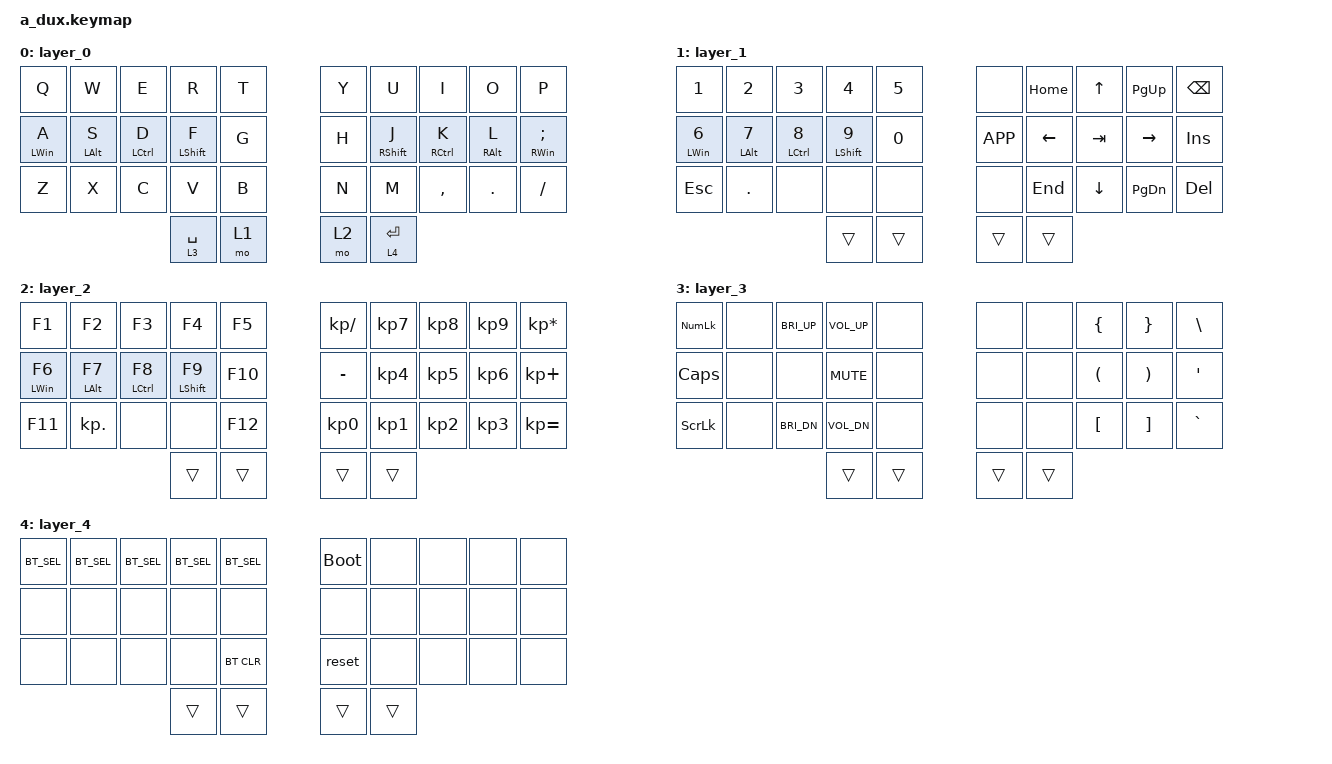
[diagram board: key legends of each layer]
/*
 * Copyright (c) 2021 The ZMK Contributors
 *
 * SPDX-License-Identifier: MIT
 */

#include <behaviors.dtsi>
#include <dt-bindings/zmk/keys.h>
#include <dt-bindings/zmk/bt.h>

/ {

    keymap {
        compatible = "zmk,keymap";
        layer_0 {
            bindings = <
// ╭─────────────┬─────────────┬─────────────┬─────────────┬─────────────╮   ╭─────────────┬─────────────┬─────────────┬─────────────┬─────────────╮
    &kp Q         &kp W         &kp E         &kp R         &kp T             &kp Y         &kp U         &kp I         &kp O         &kp P
// ├─────────────┼─────────────┼─────────────┼─────────────┼─────────────┤   ├─────────────┼─────────────┼─────────────┼─────────────┼─────────────┤
    &mt LWIN A    &mt LALT S    &mt LCTRL D   &mt LSHIFT F  &kp G             &kp H         &mt RSHIFT J  &mt RCTRL K   &mt RALT L    &mt RWIN SEMI
// ├─────────────┼─────────────┼─────────────┼─────────────┼─────────────┤   ├─────────────┼─────────────┼─────────────┼─────────────┼─────────────┤
    &kp Z         &kp X         &kp C         &kp V         &kp B             &kp N         &kp M         &kp COMMA     &kp DOT       &kp SLASH
// ╰─────────────┴─────────────┴─────────────┼─────────────┼─────────────┤   ├─────────────┼─────────────┼─────────────┴─────────────┴─────────────╯
                                              &lt 3 SPACE   &mo 1             &mo 2         &lt 4 ENTER
//                                           ╰─────────────┴─────────────╯   ╰─────────────┴─────────────╯
            >;
        };
        layer_1 {
            bindings = <
// ╭─────────────┬─────────────┬─────────────┬─────────────┬─────────────╮   ╭─────────────┬─────────────┬─────────────┬─────────────┬─────────────╮
    &kp N1        &kp N2        &kp N3        &kp N4        &kp N5            &none         &kp HOME      &kp UP        &kp PAGE_UP   &kp BACKSPACE
// ├─────────────┼─────────────┼─────────────┼─────────────┼─────────────┤   ├─────────────┼─────────────┼─────────────┼─────────────┼─────────────┤
    &mt LWIN N6   &mt LALT N7   &mt LCTRL N8  &mt LSHIFT N9 &kp N0            &kp K_APP     &kp LEFT      &kp TAB       &kp RIGHT     &kp INSERT
// ├─────────────┼─────────────┼─────────────┼─────────────┼─────────────┤   ├─────────────┼─────────────┼─────────────┼─────────────┼─────────────┤
    &kp ESCAPE    &kp DOT       &none         &none         &none             &none         &kp END       &kp DOWN      &kp PAGE_DOWN &kp DELETE
// ╰─────────────┴─────────────┴─────────────┼─────────────┼─────────────┤   ├─────────────┼─────────────┼─────────────┴─────────────┴─────────────╯
                                              &trans        &trans            &trans        &trans
//                                           ╰─────────────┴─────────────╯   ╰─────────────┴─────────────╯
            >;
        };
        layer_2 {
            bindings = <
// ╭─────────────┬─────────────┬─────────────┬─────────────┬─────────────╮   ╭─────────────┬─────────────┬─────────────┬─────────────┬─────────────╮
    &kp F1        &kp F2        &kp F3        &kp F4        &kp F5            &kp KP_DIVIDE &kp KP_N7     &kp KP_N8     &kp KP_N9     &kp KP_MULTIPLY
// ├─────────────┼─────────────┼─────────────┼─────────────┼─────────────┤   ├─────────────┼─────────────┼─────────────┼─────────────┼─────────────┤
    &mt LWIN F6   &mt LALT F7   &mt LCTRL F8  &mt LSHIFT F9 &kp F10           &kp MINUS     &kp KP_N4     &kp KP_N5     &kp KP_N6     &kp KP_PLUS
// ├─────────────┼─────────────┼─────────────┼─────────────┼─────────────┤   ├─────────────┼─────────────┼─────────────┼─────────────┼─────────────┤
    &kp F11       &kp KP_DOT    &none         &none         &kp F12           &kp KP_N0     &kp KP_N1     &kp KP_N2     &kp KP_N3     &kp KP_EQUAL
// ╰─────────────┴─────────────┴─────────────┼─────────────┼─────────────┤   ├─────────────┼─────────────┼─────────────┴─────────────┴─────────────╯
                                              &trans        &trans            &trans        &trans
//                                           ╰─────────────┴─────────────╯   ╰─────────────┴─────────────╯
            >;
        };
        layer_3 {
            bindings = <
// ╭─────────────┬─────────────┬─────────────┬─────────────┬─────────────╮   ╭─────────────┬─────────────┬─────────────┬─────────────┬─────────────╮
    &kp KP_NLCK   &none         &kp C_BRI_UP  &kp C_VOL_UP  &none             &none         &none         &kp LBRC      &kp RBRC      &kp BACKSLASH
// ├─────────────┼─────────────┼─────────────┼─────────────┼─────────────┤   ├─────────────┼─────────────┼─────────────┼─────────────┼─────────────┤
    &kp CLCK      &none         &none         &kp C_MUTE    &none             &none         &none         &kp LPAR      &kp RPAR      &kp APOSTROPHE
// ├─────────────┼─────────────┼─────────────┼─────────────┼─────────────┤   ├─────────────┼─────────────┼─────────────┼─────────────┼─────────────┤
    &kp SLCK      &none         &kp C_BRI_DN  &kp C_VOL_DN  &none             &none         &none         &kp LBKT      &kp RBKT      &kp GRAVE
// ╰─────────────┴─────────────┴─────────────┼─────────────┼─────────────┤   ├─────────────┼─────────────┼─────────────┴─────────────┴─────────────╯
                                              &trans        &trans            &trans        &trans
//                                           ╰─────────────┴─────────────╯   ╰─────────────┴─────────────╯
            >;
        };
        layer_4 {
            bindings = <
// ╭─────────────┬─────────────┬─────────────┬─────────────┬─────────────╮   ╭─────────────┬─────────────┬─────────────┬─────────────┬─────────────╮
    BT_SEL 0      BT_SEL 1      BT_SEL 2      BT_SEL 3      BT_SEL 4          &bootloader   &none         &none         &none         &none        
// ├─────────────┼─────────────┼─────────────┼─────────────┼─────────────┤   ├─────────────┼─────────────┼─────────────┼─────────────┼─────────────┤
    &none         &none         &none         &none         &none             &none         &none         &none         &none         &none         
// ├─────────────┼─────────────┼─────────────┼─────────────┼─────────────┤   ├─────────────┼─────────────┼─────────────┼─────────────┼─────────────┤
    &none         &none         &none         &none         &bt BT_CLR        &reset        &none         &none         &none         &none         
// ╰─────────────┴─────────────┴─────────────┼─────────────┼─────────────┤   ├─────────────┼─────────────┼─────────────┴─────────────┴─────────────╯
                                              &trans        &trans            &trans        &trans
//                                           ╰─────────────┴─────────────╯   ╰─────────────┴─────────────╯
            >;
        };
    };
};
